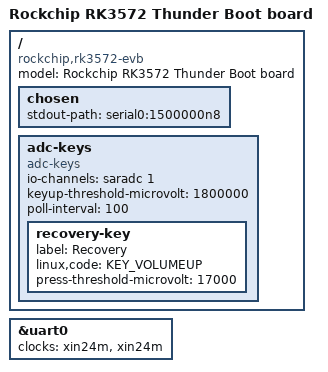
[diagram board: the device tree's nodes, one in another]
// SPDX-License-Identifier: (GPL-2.0+ OR MIT)
/*
 * Copyright (c) 2026 Rockchip Electronics Co., Ltd.
 */

/dts-v1/;

#include <dt-bindings/input/input.h>
#include "rk3572.dtsi"

/ {
	model = "Rockchip RK3572 Thunder Boot board";
	compatible = "rockchip,rk3572-evb", "rockchip,rk3572";

	chosen {
		stdout-path = "serial0:1500000n8";
	};

	adc-keys {
		compatible = "adc-keys";
		io-channels = <&saradc 1>;
		io-channel-names = "buttons";
		keyup-threshold-microvolt = <1800000>;
		poll-interval = <100>;
		bootph-all;

		recovery-key {
			bootph-all;
			label = "Recovery";
			linux,code = <KEY_VOLUMEUP>;
			press-threshold-microvolt = <17000>;
		};
	};
};

&uart0 {
	clocks = <&xin24m>, <&xin24m>;
};
